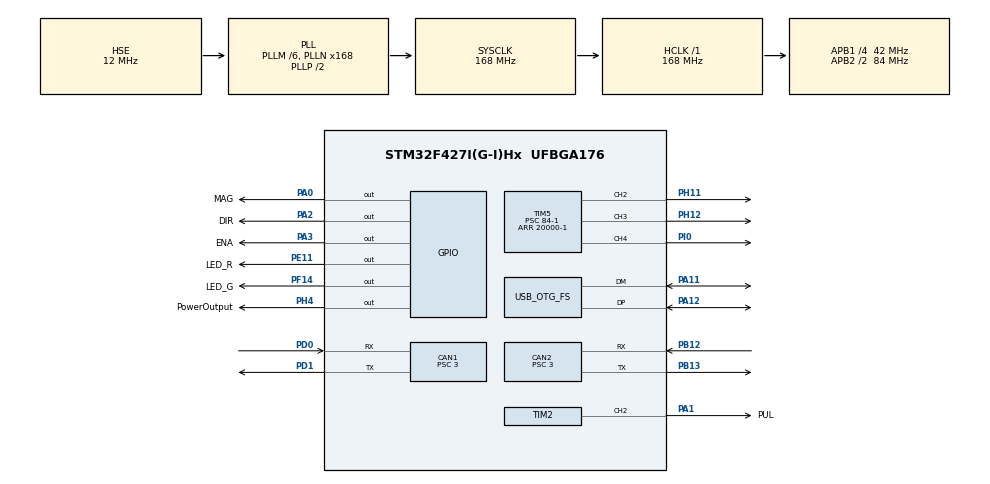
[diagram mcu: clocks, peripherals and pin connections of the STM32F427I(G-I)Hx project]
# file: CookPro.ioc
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CAN1.ABOM=ENABLE
CAN1.BS1=CAN_BS1_9TQ
CAN1.BS2=CAN_BS2_4TQ
CAN1.CalculateBaudRate=1000000
CAN1.CalculateTimeBit=1000
CAN1.CalculateTimeQuantum=71.42857142857143
CAN1.NART=ENABLE
CAN1.Prescaler=3
CAN1.RFLM=DISABLE
CAN2.ABOM=ENABLE
CAN2.BS1=CAN_BS1_9TQ
CAN2.BS2=CAN_BS2_4TQ
CAN2.CalculateBaudRate=1000000
CAN2.CalculateTimeBit=1000
CAN2.CalculateTimeQuantum=71.42857142857143
CAN2.NART=ENABLE
CAN2.Prescaler=3
FREERTOS.BinarySemaphores01=DJIMotorContolPermission,Dynamic,NULL;ReceivingReady,Dynamic,NULL;SendingReady,Dynamic,NULL
FREERTOS.Tasks01=IDLETask,-3,128,StartDefaultTask,Default,NULL,Dynamic,NULL,NULL;DJIMotorStateUpdateTask,-1,256,DJIMotorStateUpdateTaskFunc,As weak,NULL,Dynamic,NULL,NULL;DJIMotorControlTask,0,256,DJIMotorControlTaskFunc,As weak,NULL,Dynamic,NULL,NULL;DataTransmissiontask,1,256,DataTransmissionTaskFunc,As weak,NULL,Dynamic,NULL,NULL;_DEBUG_DJIControlTestTask,2,256,_DEBUG_DJIControlTestTaskFunc,As weak,NULL,Dynamic,NULL,NULL;UpperOperationTask,3,256,UpperOperationTaskFunc,As weak,NULL,Dynamic,NULL,NULL;NetherOperationTask,2,256,NetherOperationTaskFunc,As weak,NULL,Dynamic,NULL,NULL
FREERTOS.Timers01=DJIMotorWatchTimer,DJIMotorWatchTimerCallBack,osTimerPeriodic,As weak,NULL,Dynamic,NULL
FREERTOS.configENABLE_FPU=1
FREERTOS.configMAX_TASK_NAME_LEN=32
FREERTOS.configTIMER_QUEUE_LENGTH=8
FREERTOS.configTIMER_TASK_PRIORITY=4
FREERTOS.configTIMER_TASK_STACK_DEPTH=128
FREERTOS.configUSE_CO_ROUTINES=0
FREERTOS.configUSE_TIMERS=1
Mcu.Family=STM32F4
Mcu.Name=STM32F427I(G-I)Hx
Mcu.Package=UFBGA176
NVIC.CAN1_RX0_IRQn=true\:5\:0\:false\:false\:true\:true\:true\:true\:true
NVIC.CAN2_RX0_IRQn=true\:5\:0\:false\:false\:true\:true\:true\:true\:true
NVIC.OTG_FS_IRQn=true\:5\:0\:false\:false\:true\:true\:true\:true\:true
NVIC.PriorityGroup=NVIC_PRIORITYGROUP_4
NVIC.TIM1_UP_TIM10_IRQn=true\:15\:0\:false\:false\:true\:false\:false\:true\:true
NVIC.TIM2_IRQn=true\:5\:0\:false\:false\:true\:true\:true\:true\:true
NVIC.TimeBase=TIM1_UP_TIM10_IRQn
NVIC.TimeBaseIP=TIM1
PA0/WKUP.GPIO_Label=MAG
PA0/WKUP.Signal=GPIO_Output
PA1.GPIO_Label=PUL
PA1.GPIO_Speed=GPIO_SPEED_FREQ_HIGH
PA1.Signal=S_TIM2_CH2
PA11.Mode=Device_Only
PA11.Signal=USB_OTG_FS_DM
PA12.Mode=Device_Only
PA12.Signal=USB_OTG_FS_DP
PA13.Mode=Serial_Wire
PA13.Signal=SYS_JTMS-SWDIO
PA14.Mode=Serial_Wire
PA14.Signal=SYS_JTCK-SWCLK
PA2.GPIO_Label=DIR
PA2.PinState=GPIO_PIN_SET
PA2.Signal=GPIO_Output
PA3.GPIO_Label=ENA
PA3.Signal=GPIO_Output
PB12.GPIO_PuPd=GPIO_NOPULL
PB12.Mode=CAN_Activate
PB12.Signal=CAN2_RX
PB13.Mode=CAN_Activate
PB13.Signal=CAN2_TX
PD0.GPIO_Mode=GPIO_MODE_AF_PP
PD0.Mode=CAN_Activate
PD0.Signal=CAN1_RX
PD1.GPIO_Mode=GPIO_MODE_AF_PP
PD1.Mode=CAN_Activate
PD1.Signal=CAN1_TX
PE11.GPIO_Label=LED_R
PE11.PinState=GPIO_PIN_SET
PE11.Signal=GPIO_Output
PF14.GPIO_Label=LED_G
PF14.PinState=GPIO_PIN_SET
PF14.Signal=GPIO_Output
PH0/OSC_IN.Mode=HSE-External-Oscillator
PH0/OSC_IN.Signal=RCC_OSC_IN
PH1/OSC_OUT.Mode=HSE-External-Oscillator
PH1/OSC_OUT.Signal=RCC_OSC_OUT
PH11.Signal=S_TIM5_CH2
PH12.Signal=S_TIM5_CH3
PH4.GPIO_Label=PowerOutput
PH4.PinState=GPIO_PIN_SET
PH4.Signal=GPIO_Output
PI0.Signal=S_TIM5_CH4
ProjectManager.HeapSize=0x2000
ProjectManager.StackSize=0x400
ProjectManager.TargetToolchain=MDK-ARM V5
RCC.48MHZClocksFreq_Value=48000000
RCC.AHBFreq_Value=168000000
RCC.APB1CLKDivider=RCC_HCLK_DIV4
RCC.APB1Freq_Value=42000000
RCC.APB1TimFreq_Value=84000000
RCC.APB2CLKDivider=RCC_HCLK_DIV2
RCC.APB2Freq_Value=84000000
RCC.APB2TimFreq_Value=168000000
RCC.CortexFreq_Value=168000000
RCC.HCLKFreq_Value=168000000
RCC.HSE_VALUE=12000000
RCC.HSI_VALUE=16000000
RCC.LSE_VALUE=32768
RCC.PLLM=6
RCC.PLLN=168
RCC.PLLQ=7
RCC.SYSCLKFreq_VALUE=168000000
RCC.SYSCLKSource=RCC_SYSCLKSOURCE_PLLCLK
RCC.VCOOutputFreq_Value=336000000
SH.S_TIM2_CH2.0=TIM2_CH2,PWM Generation2 CH2
SH.S_TIM5_CH2.0=TIM5_CH2,PWM Generation2 CH2
SH.S_TIM5_CH3.0=TIM5_CH3,PWM Generation3 CH3
SH.S_TIM5_CH4.0=TIM5_CH4,PWM Generation4 CH4
TIM2.AutoReloadPreload=TIM_AUTORELOAD_PRELOAD_ENABLE
TIM2.Channel-PWM\ Generation2\ CH2=TIM_CHANNEL_2
TIM2.Period=1000-1
TIM2.Prescaler=84-1
TIM2.Pulse-PWM\ Generation2\ CH2=500
TIM5.AutoReloadPreload=TIM_AUTORELOAD_PRELOAD_ENABLE
TIM5.Channel-PWM\ Generation2\ CH2=TIM_CHANNEL_2
TIM5.Channel-PWM\ Generation3\ CH3=TIM_CHANNEL_3
TIM5.Channel-PWM\ Generation4\ CH4=TIM_CHANNEL_4
TIM5.Period=20000-1
TIM5.Prescaler=84-1
TIM5.Pulse-PWM\ Generation3\ CH3=0
TIM5.Pulse-PWM\ Generation4\ CH4=0
USB_DEVICE.APP_RX_DATA_SIZE-CDC_FS=256
USB_DEVICE.APP_TX_DATA_SIZE-CDC_FS=256
USB_DEVICE.CLASS_NAME_FS=CDC
USB_DEVICE.VirtualMode-CDC_FS=Cdc
USB_DEVICE.VirtualModeFS=Cdc_FS
USB_OTG_FS.VirtualMode=Device_Only
VP_FREERTOS_VS_CMSIS_V1.Mode=CMSIS_V1
VP_SYS_VS_tim1.Mode=TIM1
VP_TIM2_VS_ClockSourceINT.Mode=Internal
VP_TIM5_VS_ClockSourceINT.Mode=Internal
VP_USB_DEVICE_VS_USB_DEVICE_CDC_FS.Mode=CDC_FS
board=custom

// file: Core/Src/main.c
/* USER CODE BEGIN Header */
/**
  ******************************************************************************
  * @file           : main.c
  * @brief          : Main program body
  ******************************************************************************
  * @attention
  *
  * <h2><center>&copy; Copyright (c) 2022 STMicroelectronics.
  * All rights reserved.</center></h2>
  *
  * This software component is licensed by ST under Ultimate Liberty license
  * SLA0044, the "License"; You may not use this file except in compliance with
  * the License. You may obtain a copy of the License at:
  *                             www.st.com/SLA0044
  *
  ******************************************************************************
  */
/* USER CODE END Header */
#include "main.h"
#include "cmsis_os.h"
#include "can.h"
#include "tim.h"
#include "usb_device.h"
#include "gpio.h"

/* USER CODE BEGIN Includes */
#include "DJIMotor.h"
#include "MicroStep.h"
/* USER CODE END Includes */

void SystemClock_Config(void);
void MX_FREERTOS_Init(void);

int main(void)
{

  /* MCU Configuration--------------------------------------------------------*/

  /* Reset of all peripherals, Initializes the Flash interface and the Systick. */
  HAL_Init();

  /* Configure the system clock */
  SystemClock_Config();

  /* Initialize all configured peripherals */
  MX_GPIO_Init();
  MX_CAN1_Init();
  MX_CAN2_Init();
  MX_TIM5_Init();
  MX_TIM2_Init();
  /* USER CODE BEGIN 2 */
  MX_USB_DEVICE_Init();
  CAN_ConfigAndStart();
  HAL_TIM_Base_Start_IT(&htim2);
  HAL_TIM_PWM_Start(&htim2,TIM_CHANNEL_2);
  /* USER CODE END 2 */

  /* Call init function for freertos objects (in freertos.c) */
  MX_FREERTOS_Init();
  /* Start scheduler */
  osKernelStart();

  /* We should never get here as control is now taken by the scheduler */
  /* Infinite loop */
  while (1)
  {

  }
}

void SystemClock_Config(void)
{
  RCC_OscInitTypeDef RCC_OscInitStruct = {0};
  RCC_ClkInitTypeDef RCC_ClkInitStruct = {0};

  /** Configure the main internal regulator output voltage
  */
  __HAL_RCC_PWR_CLK_ENABLE();
  __HAL_PWR_VOLTAGESCALING_CONFIG(PWR_REGULATOR_VOLTAGE_SCALE1);
  /** Initializes the RCC Oscillators according to the specified parameters
  * in the RCC_OscInitTypeDef structure.
  */
  RCC_OscInitStruct.OscillatorType = RCC_OSCILLATORTYPE_HSE;
  RCC_OscInitStruct.HSEState = RCC_HSE_ON;
  RCC_OscInitStruct.PLL.PLLState = RCC_PLL_ON;
  RCC_OscInitStruct.PLL.PLLSource = RCC_PLLSOURCE_HSE;
  RCC_OscInitStruct.PLL.PLLM = 6;
  RCC_OscInitStruct.PLL.PLLN = 168;
  RCC_OscInitStruct.PLL.PLLP = RCC_PLLP_DIV2;
  RCC_OscInitStruct.PLL.PLLQ = 7;
  if (HAL_RCC_OscConfig(&RCC_OscInitStruct) != HAL_OK)
  {
    Error_Handler();
  }
  /** Initializes the CPU, AHB and APB buses clocks
  */
  RCC_ClkInitStruct.ClockType = RCC_CLOCKTYPE_HCLK|RCC_CLOCKTYPE_SYSCLK
                              |RCC_CLOCKTYPE_PCLK1|RCC_CLOCKTYPE_PCLK2;
  RCC_ClkInitStruct.SYSCLKSource = RCC_SYSCLKSOURCE_PLLCLK;
  RCC_ClkInitStruct.AHBCLKDivider = RCC_SYSCLK_DIV1;
  RCC_ClkInitStruct.APB1CLKDivider = RCC_HCLK_DIV4;
  RCC_ClkInitStruct.APB2CLKDivider = RCC_HCLK_DIV2;

  if (HAL_RCC_ClockConfig(&RCC_ClkInitStruct, FLASH_LATENCY_5) != HAL_OK)
  {
    Error_Handler();
  }
}

void HAL_TIM_PeriodElapsedCallback(TIM_HandleTypeDef *htim)
{
  /* USER CODE BEGIN Callback 0 */
	if(htim->Instance == TIM2)  // TIM2CH2
	{
       MicroStep_PulseNotification();
	}
  /* USER CODE END Callback 0 */
  if (htim->Instance == TIM1) {
    HAL_IncTick();
  }
}

void Error_Handler(void)
{
  __disable_irq();
  while (1)
  {
  }
}

/************************ (C) COPYRIGHT STMicroelectronics *****END OF FILE****/

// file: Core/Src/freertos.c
/* USER CODE BEGIN Header */
/**
  ******************************************************************************
  * File Name          : freertos.c
  * Description        : Code for freertos applications
  ******************************************************************************
  * @attention
  *
  * <h2><center>&copy; Copyright (c) 2022 STMicroelectronics.
  * All rights reserved.</center></h2>
  *
  * This software component is licensed by ST under Ultimate Liberty license
  * SLA0044, the "License"; You may not use this file except in compliance with
  * the License. You may obtain a copy of the License at:
  *                             www.st.com/SLA0044
  *
  ******************************************************************************
  */
/* USER CODE END Header */

#include "FreeRTOS.h"
#include "task.h"
#include "main.h"
#include "cmsis_os.h"

/* USER CODE BEGIN PD */
#define CAN_RX_QUEUE_LEN	20
#define CAN_RX_QUEUE_SIZE	16
/* USER CODE END PD */

/* USER CODE BEGIN Variables */
QueueHandle_t CAN_Rx_Queue;
/* USER CODE END Variables */
osThreadId IDLETaskHandle;
osThreadId DJIMotorStateUpdateTaskHandle;
osThreadId DJIMotorControlTaskHandle;
osThreadId DataTransmissiontaskHandle;
osThreadId _DEBUG_DJIControlTestTaskHandle;
osThreadId UpperOperationTaskHandle;
osThreadId NetherOperationTaskHandle;
osTimerId DJIMotorWatchTimerHandle;
osSemaphoreId DJIMotorContolPermissionHandle;
osSemaphoreId ReceivingReadyHandle;
osSemaphoreId SendingReadyHandle;

void StartDefaultTask(void const * argument);
void DJIMotorStateUpdateTaskFunc(void const * argument);
void DJIMotorControlTaskFunc(void const * argument);
void DataTransmissionTaskFunc(void const * argument);
void _DEBUG_DJIControlTestTaskFunc(void const * argument);
void UpperOperationTaskFunc(void const * argument);
void NetherOperationTaskFunc(void const * argument);
void DJIMotorWatchTimerCallBack(void const * argument);

extern void MX_USB_DEVICE_Init(void);
void MX_FREERTOS_Init(void); /* (MISRA C 2004 rule 8.1) */

/* GetIdleTaskMemory prototype (linked to static allocation support) */
void vApplicationGetIdleTaskMemory( StaticTask_t **ppxIdleTaskTCBBuffer, StackType_t **ppxIdleTaskStackBuffer, uint32_t *pulIdleTaskStackSize );

/* GetTimerTaskMemory prototype (linked to static allocation support) */
void vApplicationGetTimerTaskMemory( StaticTask_t **ppxTimerTaskTCBBuffer, StackType_t **ppxTimerTaskStackBuffer, uint32_t *pulTimerTaskStackSize );

/* USER CODE BEGIN GET_IDLE_TASK_MEMORY */
static StaticTask_t xIdleTaskTCBBuffer;
static StackType_t xIdleStack[configMINIMAL_STACK_SIZE];

void vApplicationGetIdleTaskMemory( StaticTask_t **ppxIdleTaskTCBBuffer, StackType_t **ppxIdleTaskStackBuffer, uint32_t *pulIdleTaskStackSize )
{
  *ppxIdleTaskTCBBuffer = &xIdleTaskTCBBuffer;
  *ppxIdleTaskStackBuffer = &xIdleStack[0];
  *pulIdleTaskStackSize = configMINIMAL_STACK_SIZE;
  /* place for user code */
}
/* USER CODE END GET_IDLE_TASK_MEMORY */

/* USER CODE BEGIN GET_TIMER_TASK_MEMORY */
static StaticTask_t xTimerTaskTCBBuffer;
static StackType_t xTimerStack[configTIMER_TASK_STACK_DEPTH];

void vApplicationGetTimerTaskMemory( StaticTask_t **ppxTimerTaskTCBBuffer, StackType_t **ppxTimerTaskStackBuffer, uint32_t *pulTimerTaskStackSize )
{
  *ppxTimerTaskTCBBuffer = &xTimerTaskTCBBuffer;
  *ppxTimerTaskStackBuffer = &xTimerStack[0];
  *pulTimerTaskStackSize = configTIMER_TASK_STACK_DEPTH;
  /* place for user code */
}
/* USER CODE END GET_TIMER_TASK_MEMORY */

void MX_FREERTOS_Init(void) {

  /* Create the semaphores(s) */
  /* definition and creation of DJIMotorContolPermission */
  osSemaphoreDef(DJIMotorContolPermission);
  DJIMotorContolPermissionHandle = osSemaphoreCreate(osSemaphore(DJIMotorContolPermission), 1);

  /* definition and creation of ReceivingReady */
  osSemaphoreDef(ReceivingReady);
  ReceivingReadyHandle = osSemaphoreCreate(osSemaphore(ReceivingReady), 1);

  /* definition and creation of SendingReady */
  osSemaphoreDef(SendingReady);
  SendingReadyHandle = osSemaphoreCreate(osSemaphore(SendingReady), 1);

  /* Create the timer(s) */
  /* definition and creation of DJIMotorWatchTimer */
  osTimerDef(DJIMotorWatchTimer, DJIMotorWatchTimerCallBack);
  DJIMotorWatchTimerHandle = osTimerCreate(osTimer(DJIMotorWatchTimer), osTimerPeriodic, NULL);

  /* USER CODE BEGIN RTOS_QUEUES */
  /* add queues, ... */
  CAN_Rx_Queue = xQueueCreate((UBaseType_t)CAN_RX_QUEUE_LEN,(UBaseType_t)CAN_RX_QUEUE_SIZE);
  if(NULL == CAN_Rx_Queue)
  {
	  // Queue Create Error
  }
  /* USER CODE END RTOS_QUEUES */

  /* Create the thread(s) */
  /* definition and creation of IDLETask */
  osThreadDef(IDLETask, StartDefaultTask, osPriorityIdle, 0, 128);
  IDLETaskHandle = osThreadCreate(osThread(IDLETask), NULL);

  /* definition and creation of DJIMotorStateUpdateTask */
  osThreadDef(DJIMotorStateUpdateTask, DJIMotorStateUpdateTaskFunc, osPriorityBelowNormal, 0, 256);
  DJIMotorStateUpdateTaskHandle = osThreadCreate(osThread(DJIMotorStateUpdateTask), NULL);

  /* definition and creation of DJIMotorControlTask */
  osThreadDef(DJIMotorControlTask, DJIMotorControlTaskFunc, osPriorityNormal, 0, 256);
  DJIMotorControlTaskHandle = osThreadCreate(osThread(DJIMotorControlTask), NULL);

  /* definition and creation of DataTransmissiontask */
  osThreadDef(DataTransmissiontask, DataTransmissionTaskFunc, osPriorityAboveNormal, 0, 256);
  DataTransmissiontaskHandle = osThreadCreate(osThread(DataTransmissiontask), NULL);

  /* definition and creation of _DEBUG_DJIControlTestTask */
  osThreadDef(_DEBUG_DJIControlTestTask, _DEBUG_DJIControlTestTaskFunc, osPriorityHigh, 0, 256);
  _DEBUG_DJIControlTestTaskHandle = osThreadCreate(osThread(_DEBUG_DJIControlTestTask), NULL);

  /* definition and creation of UpperOperationTask */
  osThreadDef(UpperOperationTask, UpperOperationTaskFunc, osPriorityRealtime, 0, 256);
  UpperOperationTaskHandle = osThreadCreate(osThread(UpperOperationTask), NULL);

  /* definition and creation of NetherOperationTask */
  osThreadDef(NetherOperationTask, NetherOperationTaskFunc, osPriorityHigh, 0, 256);
  NetherOperationTaskHandle = osThreadCreate(osThread(NetherOperationTask), NULL);

}

void StartDefaultTask(void const * argument)
{
  /* init code for USB_DEVICE */
  MX_USB_DEVICE_Init();
  for(;;)
  {
    osDelay(1);
  }
}

__weak void DJIMotorStateUpdateTaskFunc(void const * argument)
{
  for(;;)
  {
    osDelay(1);
  }
}

__weak void DJIMotorControlTaskFunc(void const * argument)
{
  for(;;)
  {
    osDelay(1);
  }
}

__weak void DataTransmissionTaskFunc(void const * argument)
{
  for(;;)
  {
    osDelay(1);
  }
}

__weak void _DEBUG_DJIControlTestTaskFunc(void const * argument)
{
  for(;;)
  {
    osDelay(1);
  }
}

__weak void UpperOperationTaskFunc(void const * argument)
{
  for(;;)
  {
    osDelay(1);
  }
}

__weak void NetherOperationTaskFunc(void const * argument)
{
  for(;;)
  {
    osDelay(1);
  }
}

/* DJIMotorWatchTimerCallBack function */
__weak void DJIMotorWatchTimerCallBack(void const * argument)
{
}

/************************ (C) COPYRIGHT STMicroelectronics *****END OF FILE****/
